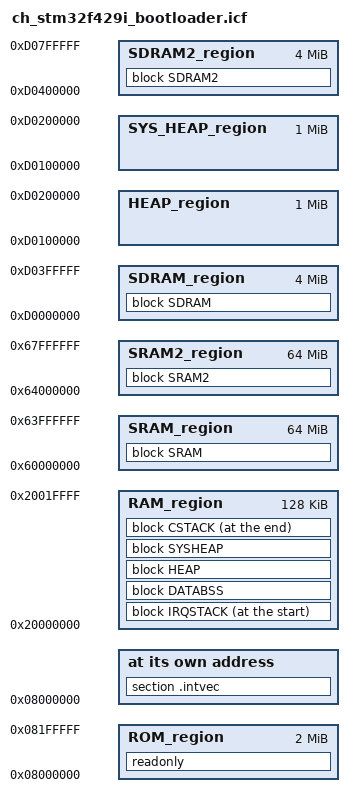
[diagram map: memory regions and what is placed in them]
/*###ICF### Section handled by ICF editor, don't touch! ****/
/*-Editor annotation file-*/
/* IcfEditorFile="$TOOLKIT_DIR$\config\ide\IcfEditor\cortex_v1_0.xml" */
/*-Specials-*/
define symbol __ICFEDIT_intvec_start__ = 0x08000000;
/*-Memory Regions-*/
define symbol __ICFEDIT_region_ROM_start__ = 0x08000000;
define symbol __ICFEDIT_region_ROM_end__   = 0x081FFFFF;
define symbol __ICFEDIT_region_RAM_start__ = 0x20000000;
define symbol __ICFEDIT_region_RAM_end__   = 0x2001FFFF;
define symbol __SRAM_start__               = 0x60000000;
define symbol __SRAM_end__                 = 0x63FFFFFF;
define symbol __SRAM2_start__              = 0x64000000;
define symbol __SRAM2_end__                = 0x67FFFFFF;
define symbol __SDRAM_start__              = 0xd0000000;
define symbol __SDRAM_end__                = 0xd03FFFFF;
define symbol __SDRAM2_start__             = 0xd0400000;
define symbol __SDRAM2_end__               = 0xd07FFFFF;
define symbol __SDRAM_heap_start__         = 0xd0100000;
define symbol __SDRAM_heap_end__           = 0xd0200000;
define symbol __heap_base__                = __SDRAM_heap_start__;
define symbol __heap_end__                 = __SDRAM_heap_end__;
/*-Sizes-*/
define symbol __ICFEDIT_size_cstack__ = 0xc00;
define symbol __ICFEDIT_size_heap__   = 0x800;
/**** End of ICF editor section. ###ICF###*/

/* Size of the IRQ Stack (Main Stack).*/
define symbol __ICFEDIT_size_irqstack__   = 0x400;

define memory mem with size = 4G;
define region ROM_region   = mem:[from __ICFEDIT_region_ROM_start__   to __ICFEDIT_region_ROM_end__];
define region RAM_region   = mem:[from __ICFEDIT_region_RAM_start__   to __ICFEDIT_region_RAM_end__];
define region SRAM_region  = mem:[from __SRAM_start__ to __SRAM_end__];
define region SRAM2_region  = mem:[from __SRAM2_start__ to __SRAM2_end__];
define region SDRAM_region = mem:[from __SDRAM_start__ to __SDRAM_end__];
define region SDRAM2_region = mem:[from __SDRAM2_start__ to __SDRAM2_end__];
define region HEAP_region = mem:[from __heap_base__ to __heap_end__];
define region SYS_HEAP_region = mem:[from __SDRAM_heap_start__ to __SDRAM_heap_end__];

define block CSTACK    with alignment = 8, size = __ICFEDIT_size_cstack__   {section CSTACK};
define block IRQSTACK  with alignment = 8, size = __ICFEDIT_size_irqstack__ {};
define block HEAP      with alignment = 8, size = __ICFEDIT_size_heap__     {};
/* define block SYSHEAP   with alignment = 8, size = 1M {section SYSHEAP}; */
define block SYSHEAP   with alignment = 8 {section SYSHEAP};
define block DATABSS   with alignment = 8 {readwrite, zeroinit};
define block SDRAM     with alignment = 8, size = 4M {section SDRAM};
define block SDRAM2     with alignment = 8, size = 0x200000{section SDRAM2};
define block SRAM     with alignment = 8, size = 0x200000{section SRAM};
define block SRAM2     with alignment = 8, size = 0x200000{section SRAM2};
initialize by copy { readwrite };
do not initialize  { section .noinit };

keep { section .intvec };

place at address mem:__ICFEDIT_intvec_start__ {section .intvec};
place in ROM_region                           {readonly};
place at start of RAM_region                  {block IRQSTACK};
place in RAM_region                           {block DATABSS, block HEAP};
place in RAM_region                      {block SYSHEAP};
place at end of RAM_region                    {block CSTACK};
place in SDRAM_region {block SDRAM};
place in SDRAM2_region {block SDRAM2};
place in SRAM_region {block SRAM};
place in SRAM2_region {block SRAM2};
